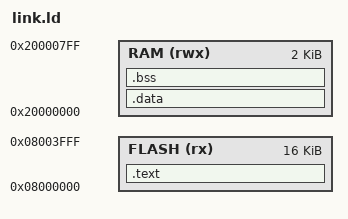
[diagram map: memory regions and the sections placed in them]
/* linker.ld */

MEMORY
{
    FLASH (rx) : ORIGIN = 0x08000000, LENGTH = 16K
    RAM   (rwx) : ORIGIN = 0x20000000, LENGTH = 2K
}

ENTRY(Reset_Handler)

SECTIONS
{
    .text :
    {
        KEEP(*(.vectors))
        *(.text*)
        *(.rodata*)
        . = ALIGN(4);
    } > FLASH

    .data : AT(ADDR(.text) + SIZEOF(.text))
    {
        . = ALIGN(4);
        _data_start = .;
        *(.data*)
        . = ALIGN(4);
        _data_end = .;
    } > RAM

        _sidata = LOADADDR(.data);

    .bss :
    {
        . = ALIGN(4);
        _bss_start = .;
        *(.bss*)
        . = ALIGN(4);
        _bss_end = .;
    } > RAM

    _estack = ORIGIN(RAM) + LENGTH(RAM);
}
